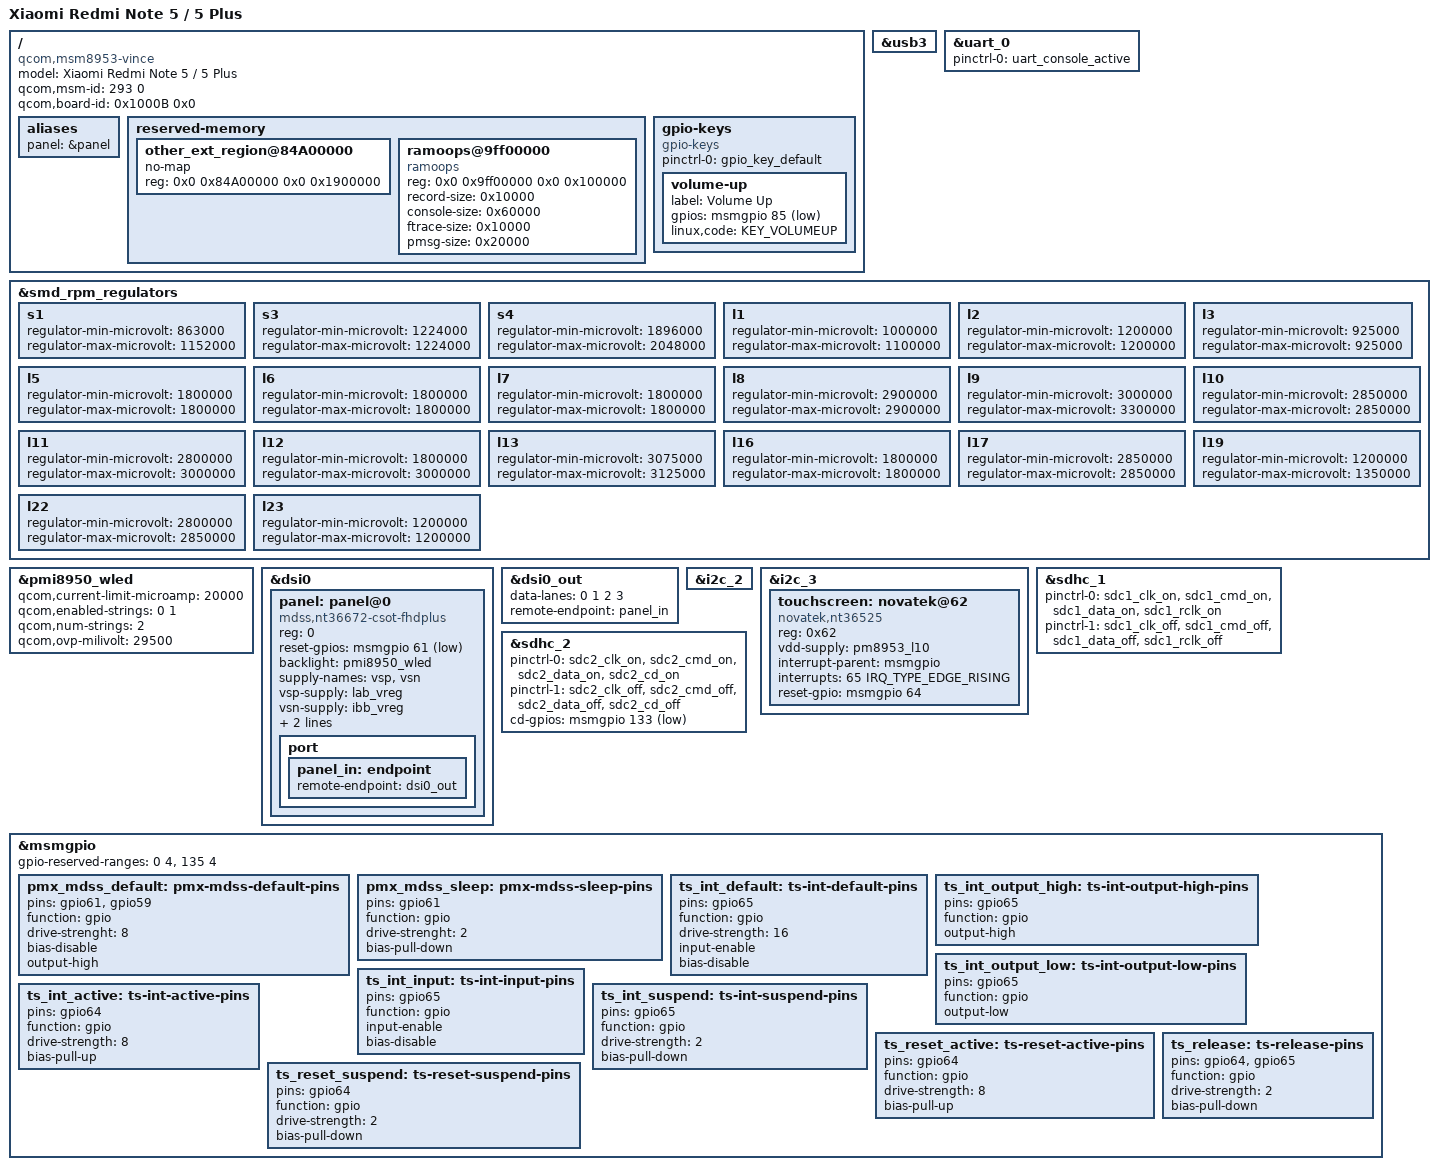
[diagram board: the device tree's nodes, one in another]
/* Copyright (c) 2017,2020 The Linux Foundation. All rights reserved.
 *
 * This program is free software; you can redistribute it and/or modify
 * it under the terms of the GNU General Public License version 2 and
 * only version 2 as published by the Free Software Foundation.
 *
 * This program is distributed in the hope that it will be useful,
 * but WITHOUT ANY WARRANTY; without even the implied warranty of
 * MERCHANTABILITY or FITNESS FOR A PARTICULAR PURPOSE.  See the
 * GNU General Public License for more details.
 */
/dts-v1/;

#include "msm8953-pm8953.dtsi"
#include "pmi8950.dtsi"
#include <dt-bindings/leds/common.h>
#include <dt-bindings/gpio/gpio.h>

/ {
	model = "Xiaomi Redmi Note 5 / 5 Plus";
	compatible = "qcom,msm8953-vince", "qcom,msm8953-xiaomi", "qcom,msm8953";

	qcom,msm-id = <293 0>;
	qcom,board-id= <0x1000B 0x0>;

	aliases {
		panel = &panel;
	};

	reserved-memory {
		/delete-node/other_ext_region@85b00000;

		other_ext_region@84A00000 {
			no-map;
			reg = <0x0 0x84A00000 0x0 0x1900000>;
		};

		ramoops@9ff00000 {
			compatible = "ramoops";
			reg = <0x0 0x9ff00000 0x0 0x100000>;
			record-size = <0x10000>;
			console-size = <0x60000>;
			ftrace-size = <0x10000>;
			pmsg-size = <0x20000>;
			status = "okay";
		};
	};

	gpio-keys {
		compatible = "gpio-keys";

		pinctrl-names = "default";
		pinctrl-0 = <&gpio_key_default>;
		volume-up {
			label = "Volume Up";
			gpios = <&msmgpio 85 GPIO_ACTIVE_LOW>;
			linux,code = <KEY_VOLUMEUP>;
		};
	};

};

&usb3 {
	status = "okay";
};

&uart_0 {
	status = "okay";
	pinctrl-names = "default";
	pinctrl-0 = <&uart_console_active>;
};

&smd_rpm_regulators {
	s1 {
		regulator-min-microvolt = <863000>;
		regulator-max-microvolt = <1152000>;
	};

	s3 {
		regulator-min-microvolt = <1224000>;
		regulator-max-microvolt = <1224000>;
	};

	s4 {
		regulator-min-microvolt = <1896000>;
		regulator-max-microvolt = <2048000>;
	};

	l1 {
		regulator-min-microvolt = <1000000>;
		regulator-max-microvolt = <1100000>;
	};

	l2 {
		regulator-min-microvolt = <1200000>;
		regulator-max-microvolt = <1200000>;
	};

	l3 {
		regulator-min-microvolt = <925000>;
		regulator-max-microvolt = <925000>;
	};

	l5 {
		regulator-min-microvolt = <1800000>;
		regulator-max-microvolt = <1800000>;
	};

	l6 {
		regulator-min-microvolt = <1800000>;
		regulator-max-microvolt = <1800000>;
	};

	l7 {
		regulator-min-microvolt = <1800000>;
		regulator-max-microvolt = <1800000>;
	};

	l8 {
		regulator-min-microvolt = <2900000>;
		regulator-max-microvolt = <2900000>;
	};

	l9 {
		regulator-min-microvolt = <3000000>;
		regulator-max-microvolt = <3300000>;
	};

	l10 {
		regulator-min-microvolt = <2850000>;
		regulator-max-microvolt = <2850000>;
	};

	l11 {
		regulator-min-microvolt = <2800000>;
		regulator-max-microvolt = <3000000>;
	};

	l12 {
		regulator-min-microvolt = <1800000>;
		regulator-max-microvolt = <3000000>;
	};

	l13 {
		regulator-min-microvolt = <3075000>;
		regulator-max-microvolt = <3125000>;
	};

	l16 {
		regulator-min-microvolt = <1800000>;
		regulator-max-microvolt = <1800000>;
	};

	l17 {
		regulator-min-microvolt = <2850000>;
		regulator-max-microvolt = <2850000>;
	};

	l19 {
		regulator-min-microvolt = <1200000>;
		regulator-max-microvolt = <1350000>;
	};

	l22 {
		regulator-min-microvolt = <2800000>;
		regulator-max-microvolt = <2850000>;
	};

	l23 {
		regulator-min-microvolt = <1200000>;
		regulator-max-microvolt = <1200000>;
	};
};

&pmi8950_wled {
	status = "okay";

	qcom,current-limit-microamp = <20000>;
	qcom,enabled-strings = <0 1>;
	qcom,num-strings = <2>;
	qcom,ovp-milivolt = <29500>;
};

&dsi0 {
	panel: panel@0 {
		compatible = "mdss,nt36672-csot-fhdplus";
		reg = <0>;

		reset-gpios = <&msmgpio 61 GPIO_ACTIVE_LOW>;

		backlight = <&pmi8950_wled>;

		supply-names = "vsp", "vsn";
		vsp-supply = <&lab_vreg>;
		vsn-supply = <&ibb_vreg>;

		pinctrl-names = "default", "sleep";
		pinctrl-0 = <&pmx_mdss_default &mdss_te_default>;
		pinctrl-1 = <&pmx_mdss_sleep &mdss_te_default>;

		port {
			panel_in: endpoint {
				remote-endpoint = <&dsi0_out>;
			};
		};
	};
};

&dsi0_out {
	data-lanes = <0 1 2 3>;
	remote-endpoint = <&panel_in>;
};

&i2c_2 {
        status = "okay";
};

&i2c_3 {
	status = "okay";
	touchscreen: novatek@62 {
		compatible = "novatek,nt36525";
		reg = <0x62>;
		vdd-supply = <&pm8953_l10>;
		interrupt-parent = <&msmgpio>;
		interrupts = <65 IRQ_TYPE_EDGE_RISING>;
		reset-gpio = <&msmgpio 64 0x0 /* GPIO_ACTIVE_HIGH */ >; 	
		};
};

&sdhc_1 {
	status = "okay";

	pinctrl-names = "default", "sleep";
	pinctrl-0 = <&sdc1_clk_on &sdc1_cmd_on &sdc1_data_on  &sdc1_rclk_on>;
	pinctrl-1 = <&sdc1_clk_off &sdc1_cmd_off &sdc1_data_off &sdc1_rclk_off>;
};

&sdhc_2 {
	status = "okay";

	pinctrl-names = "default", "sleep";
	pinctrl-0 = <&sdc2_clk_on &sdc2_cmd_on &sdc2_data_on &sdc2_cd_on>;
	pinctrl-1 = <&sdc2_clk_off &sdc2_cmd_off &sdc2_data_off &sdc2_cd_off>;

	cd-gpios = <&msmgpio 133 GPIO_ACTIVE_LOW>;
};

&msmgpio {
	gpio-reserved-ranges = <0 4>, <135 4>;

	pmx_mdss_default: pmx-mdss-default-pins {
		pins = "gpio61", "gpio59";
		function = "gpio";
		drive-strenght = <8>;
		bias-disable;
		output-high;
	};

	pmx_mdss_sleep: pmx-mdss-sleep-pins {
		pins = "gpio61";
		function = "gpio";
		drive-strenght = <2>;
		bias-pull-down;
	};

	ts_int_default: ts-int-default-pins {
		pins = "gpio65";
		function = "gpio";
		drive-strength = <16>;
		input-enable;
		bias-disable;
	};

	ts_int_output_high: ts-int-output-high-pins {
		pins = "gpio65";
		function = "gpio";
		output-high;
	};

	ts_int_output_low: ts-int-output-low-pins {
		pins = "gpio65";
		function = "gpio";
		output-low;
	};

	ts_int_input: ts-int-input-pins {
		pins = "gpio65";
		function = "gpio";
		input-enable;
		bias-disable;
	};

	ts_int_active: ts-int-active-pins {
		pins = "gpio64";
		function = "gpio";
		drive-strength = <8>;
		bias-pull-up;
	};

	ts_int_suspend: ts-int-suspend-pins {
		pins = "gpio65";
		function = "gpio";
		drive-strength = <2>;
		bias-pull-down;
	};

	ts_reset_active: ts-reset-active-pins {
		pins = "gpio64";
		function = "gpio";
		drive-strength = <8>;
		bias-pull-up;
	};

	ts_reset_suspend: ts-reset-suspend-pins {
		pins = "gpio64";
		function = "gpio";
		drive-strength = <2>;
		bias-pull-down;
	};

	ts_release: ts-release-pins {
		pins = "gpio64", "gpio65";
		function = "gpio";
		drive-strength = <2>;
		bias-pull-down;
	};

};
